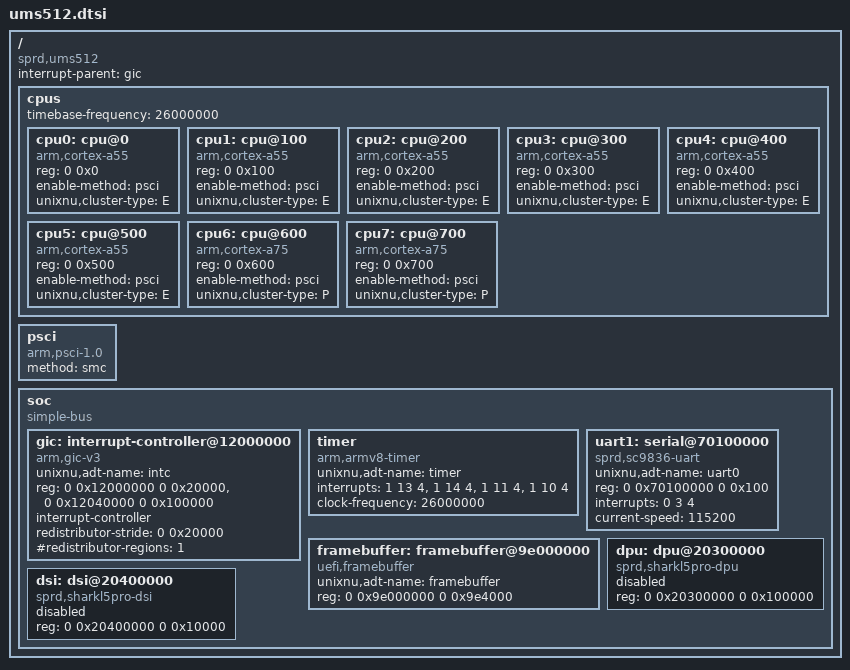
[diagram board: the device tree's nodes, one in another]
/*
 * Unisoc UMS512 / SharkL5Pro (T610 family) shared device tree.
 *
 * Sources of every value in this file:
 *   - vendor boot.bin appended DTB, analysis/extracted/boot/boot-dtb.dtb
 *     (compatible "sprd,ums512", model "Unisoc UMS512 SoC")
 *   - hxzbaka/UniXNU-t610yp (same SoC family): UART 0x70100000, GICD
 *     0x12000000, GICR 0x12040000 stride 0x20000, timer PPI 13/14/11/10,
 *     6x Cortex-A55 + 2x Cortex-A75, framebuffer at 0x9e000000.
 *
 * Only the nodes UniXNU needs to build the ADT are described here.  The board
 * DTS includes this file and adds DRAM, reserved-memory and the panel/touch
 * wiring.
 */

/ {
	compatible = "sprd,ums512";
	#address-cells = <2>;
	#size-cells = <2>;
	interrupt-parent = <&gic>;

	cpus {
		#address-cells = <2>;
		#size-cells = <0>;
		/* 26 MHz architectural timer (vendor FDT clock-frequency 0x18cba80). */
		timebase-frequency = <26000000>;

		cpu0: cpu@0 {
			device_type = "cpu";
			compatible = "arm,cortex-a55";
			reg = <0 0x0>;
			enable-method = "psci";
			unixnu,cluster-type = "E";
		};
		cpu1: cpu@100 {
			device_type = "cpu";
			compatible = "arm,cortex-a55";
			reg = <0 0x100>;
			enable-method = "psci";
			unixnu,cluster-type = "E";
		};
		cpu2: cpu@200 {
			device_type = "cpu";
			compatible = "arm,cortex-a55";
			reg = <0 0x200>;
			enable-method = "psci";
			unixnu,cluster-type = "E";
		};
		cpu3: cpu@300 {
			device_type = "cpu";
			compatible = "arm,cortex-a55";
			reg = <0 0x300>;
			enable-method = "psci";
			unixnu,cluster-type = "E";
		};
		cpu4: cpu@400 {
			device_type = "cpu";
			compatible = "arm,cortex-a55";
			reg = <0 0x400>;
			enable-method = "psci";
			unixnu,cluster-type = "E";
		};
		cpu5: cpu@500 {
			device_type = "cpu";
			compatible = "arm,cortex-a55";
			reg = <0 0x500>;
			enable-method = "psci";
			unixnu,cluster-type = "E";
		};
		cpu6: cpu@600 {
			device_type = "cpu";
			compatible = "arm,cortex-a75";
			reg = <0 0x600>;
			enable-method = "psci";
			unixnu,cluster-type = "P";
		};
		cpu7: cpu@700 {
			device_type = "cpu";
			compatible = "arm,cortex-a75";
			reg = <0 0x700>;
			enable-method = "psci";
			unixnu,cluster-type = "P";
		};
	};

	psci {
		compatible = "arm,psci-1.0", "arm,psci-0.2";
		method = "smc";
	};

	soc {
		compatible = "simple-bus";
		#address-cells = <2>;
		#size-cells = <2>;
		ranges;

		gic: interrupt-controller@12000000 {
			compatible = "arm,gic-v3";
			unixnu,adt-name = "intc";
			reg = <0 0x12000000 0 0x20000>,	/* GICD */
			      <0 0x12040000 0 0x100000>;	/* GICR, 8 frames */
			#interrupt-cells = <3>;
			#address-cells = <0>;
			interrupt-controller;
			redistributor-stride = <0 0x20000>;
			#redistributor-regions = <1>;
		};

		timer {
			compatible = "arm,armv8-timer";
			unixnu,adt-name = "timer";
			/* Vendor FDT: PPI 13/14/11/10, level high. ArmPkg defaults
			 * (29/30/27/26) leave DXE stuck on the first timer event. */
			interrupts = <1 13 4>, <1 14 4>, <1 11 4>, <1 10 4>;
			clock-frequency = <26000000>;
		};

		uart1: serial@70100000 {
			compatible = "sprd,sc9836-uart";
			unixnu,adt-name = "uart0";
			reg = <0 0x70100000 0 0x100>;
			interrupts = <0 3 4>;
			current-speed = <115200>;
			status = "okay";
		};

		/* Framebuffer left running by the stock bootloader.
		 *
		 * 0x9e000000 is the U-Boot "logobuffer" (size 0x9e4000, i.e. 10.4 MiB;
		 * uboot.bin string "logobuffer@9e000000").  The Linux kernel later
		 * reserves 0xfd708000 / 0x1e5a000 as its framebuffer, but that region is
		 * only valid after the vendor DPU driver has run, so the firmware handoff
		 * uses the bootloader buffer instead (same choice as UniXNU-t610yp).
		 * 1200x1920x4 = 0x8ca000 bytes fit inside the 0x9e4000 logobuffer.
		 */
		framebuffer: framebuffer@9e000000 {
			compatible = "uefi,framebuffer";
			unixnu,adt-name = "framebuffer";
			reg = <0 0x9e000000 0 0x9e4000>;
			status = "okay";
		};

		dpu: dpu@20300000 {
			compatible = "sprd,sharkl5pro-dpu";
			reg = <0 0x20300000 0 0x100000>;
			status = "disabled";
		};

		dsi: dsi@20400000 {
			compatible = "sprd,sharkl5pro-dsi";
			reg = <0 0x20400000 0 0x10000>;
			status = "disabled";
		};
	};
};
